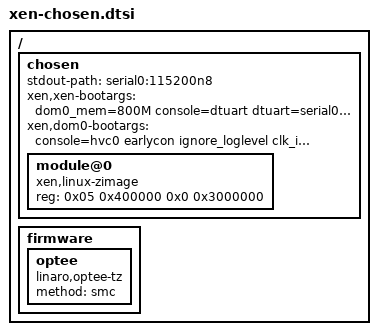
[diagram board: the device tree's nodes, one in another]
/*
 * Device Tree default chosen node for systems running XEN hypervisor
 *
 * Copyright (C) 2019 EPAM Systems.
 *
 * This file is licensed under the terms of the GNU General Public License
 * version 2.  This program is licensed "as is" without any warranty of any
 * kind, whether express or implied.
 */


/ {
	chosen {
		stdout-path = "serial0:115200n8";
		xen,xen-bootargs = "dom0_mem=800M console=dtuart dtuart=serial0 dom0_max_vcpus=4 bootscrub=0 loglvl=info sched_ratelimit_us=100 hmp-unsafe=true xsm=dummy";
		xen,dom0-bootargs = "console=hvc0 earlycon ignore_loglevel clk_ignore_unused root=/dev/mmcblk0p2 pvrsrvkm.DriverMode=0 cma=256M";

		#address-cells = <0x02>;
		#size-cells = <0x02>;

		module@0 {
			compatible = "xen,linux-zimage\0xen,multiboot-module";
			reg = <0x05 0x400000 0x0 0x3000000>;
		};
	};

	firmware {
		optee {
			compatible = "linaro,optee-tz";
			method = "smc";
		};
	};
};
